# SAM9X75D1G device description
Architecture: ARM926EJ-S; Family: SAM9; Series: SAM9X7
Registers are 32-bit, read-write, reset 0x0 unless marked. A register's access mark holds for its fields unless they carry their own. Offsets are from the block's base; [hi:lo] are bit positions; {n}, {i} and the like mark numbered series.

## CSI — CSI Host Controller
Instances: CSI 0xF8058000
0x04 CSI_N_LANES reset 0x1 — CSI Lane Configuration Register
  [0] N_LANES — Number of active data lanes
0x08 CSI_CSI2_RESETN — CSI Reset Control Register
  [0] CSI2_RESETN — Internal controller logic reset
    0=Resets the internal controller logic; 1=CSI exits Reset state
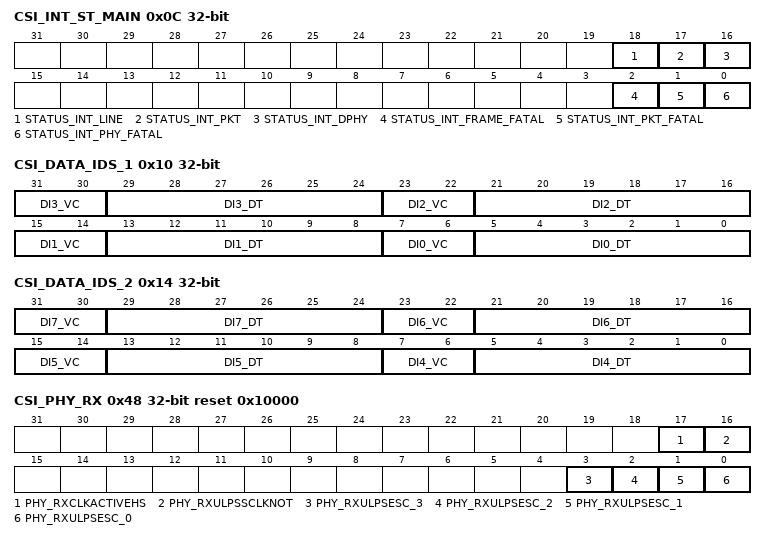
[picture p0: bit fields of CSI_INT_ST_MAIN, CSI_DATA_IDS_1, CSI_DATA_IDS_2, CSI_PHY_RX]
0x0C CSI_INT_ST_MAIN ro — CSI Main Interrupt Status Register
  [18] STATUS_INT_LINE — CSI_INT_LINE Register Event (Cleared on Read)
    0=No event occurred in the CSI_INT_ST_LINE register since the last CSI_INT_ST_MAIN read; 1=Indicates if an event occurred in the CSI_INT_ST_LINE register since the last CSI_INT_ST_MAIN read
  [17] STATUS_INT_PKT — CSI_INT_ST_PKT Register Event (Cleared on Read)
    0=No event occurred in the CSI_INT_ST_PKT register since the last CSI_INT_ST_MAIN read; 1=Indicates if an event occurred in the CSI_INT_ST_PKT register since the last CSI_INT_ST_MAIN read
  [16] STATUS_INT_DPHY — CSI_INT_ST_DPHY Register Event (Cleared on Read)
    0=No event occurred in the CSI_INT_ST_DPHY register since the last CSI_INT_ST_MAIN read; 1=Indicates if an event occurred in the CSI_INT_ST_DPHY register since the last CSI_INT_ST_MAIN read
  [2] STATUS_INT_FRAME_FATAL — CSI_INT_ST_FRAME_FATAL Register Event (Cleared on Read)
    0=No event occurred in the CSI_INT_ST_FRAME_FATAL register since the last CSI_INT_ST_MAIN read; 1=Indicates if an event occurred in the CSI_INT_ST_FRAME_FATAL register since the last CSI_INT_ST_MAIN read
  [1] STATUS_INT_PKT_FATAL — CSI_INT_ST_PKT_FATAL Register Event (Cleared on Read)
    0=No event occurred in the CSI_INT_ST_PKT_FATAL register since the last CSI_INT_ST_MAIN read; 1=Indicates if an event occurred in the CSI_INT_ST_PKT_FATAL register since the last CSI_INT_ST_MAIN read
  [0] STATUS_INT_PHY_FATAL — CSI_INT_ST_PHY_FATAL Register Event (Cleared on Read)
    0=No event occurred in the CSI_INT_ST_PHY_FATAL register since the last CSI_INT_ST_MAIN read; 1=Indicates if an event occurred in the CSI_INT_ST_PHY_FATAL register since the last CSI_INT_ST_MAIN read
0x10 CSI_DATA_IDS_1 — CSI Data Identifier Register 1
  [8n+7:8n+6] DI{n}_VC (n=0..3) — Virtual Channel for Programmed data ID {n}
  [8n+5:8n] DI{n}_DT (n=0..3) — Data Type for Programmed data ID {n}
0x14 CSI_DATA_IDS_2 — CSI Data Identifier Register 2
  [8n-25:8n-26] DI{n}_VC (n=4..7) — Virtual Channel for Programmed data ID {n}
  [8n-27:8n-32] DI{n}_DT (n=4..7) — Data Type for Programmed data ID {n}
0x40 CSI_PHY_SHUTDOWNZ — CSI D-PHY Shutdown Register
  [0] PHY_SHUTDOWNZ — Shutdown input buffer
    0=Puts the D-PHY in Shutdown mode. All analog blocks are in Power-down mode and digital logic is cleared.; 1=D-PHY exits Shutdown mode
0x44 CSI_DPHY_RSTZ — CSI D-PHY Reset Register
  [0] DPHY_RSTZ — D-PHY Reset Control
    0=Resets the D-PHY; 1=D-PHY exits Reset state
0x48 CSI_PHY_RX ro reset 0x10000 — CSI D-PHY Receive Status Register
  [17] PHY_RXCLKACTIVEHS — D-PHY Receives a DDR clock
    0=No DDR clock received; 1=Indicates that D-PHY clock lane is actively receiving a DDR clock
  [16] PHY_RXULPSSCLKNOT — Clock Lane Power Status
    0=Indicates that D-PHY Clock Lane module has entered the Ultra-Low-Power Mode; 1=Clock Lane is not ULP Mode
  [3] PHY_RXULPSESC_3 — Lane 3 Ultra-Low-Power Status
    0=Data lane 3 module is not in ULP Mode; 1=Data lane 3 module has entered ULP Mode
  [2] PHY_RXULPSESC_2 — Data Lane 2 Ultra-Low-Power Status
    0=Data lane 2 module is not in ULP Mode; 1=Data lane 2 module has entered ULP Mode
  [1] PHY_RXULPSESC_1 — Data Lane 1 Ultra-Low-Power Status
    0=Data lane 1 module is not in ULP Mode; 1=Data lane 1 module has entered ULP Mode
  [0] PHY_RXULPSESC_0 — Data Lane 0 Ultra-Low-Power Status
    0=Data lane 0 module is not in Ultra-Low-Power (ULP) Mode; 1=Data lane 0 module has entered ULP Mode
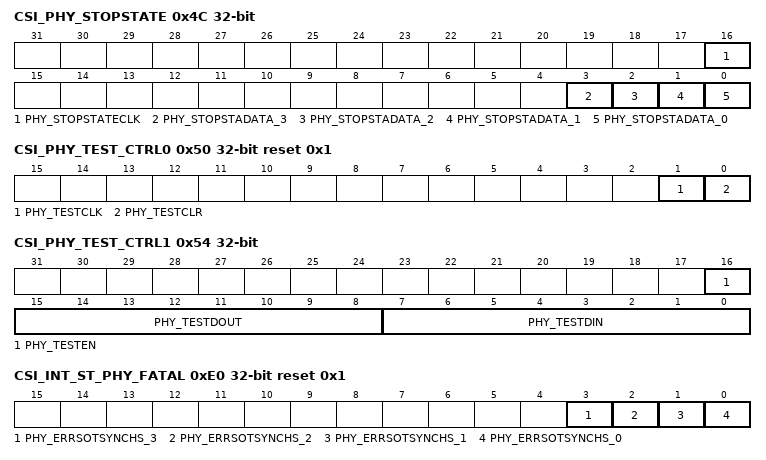
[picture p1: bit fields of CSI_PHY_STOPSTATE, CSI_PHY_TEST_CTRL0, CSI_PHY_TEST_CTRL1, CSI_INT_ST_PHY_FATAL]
0x4C CSI_PHY_STOPSTATE ro — CSI D-PHY Stop State Register
  [16] PHY_STOPSTATECLK — Clock Lane Stop State Status
    0=Clock lane module is not in Stop state; 1=Clock lane module is in Stop state
  [3] PHY_STOPSTADATA_3 — Data Lane 3 Stop State Status
    0=Data lane 3 module is not in Stop state; 1=Data lane 3 module has entered Stop state
  [2] PHY_STOPSTADATA_2 — Data Lane 2 Stop State Status
    0=Data lane 2 module is not in Stop state; 1=Data lane 2 module has entered Stop state
  [1] PHY_STOPSTADATA_1 — Data Lane 1 Stop State Status
    0=Lane 1 module is not in Stop state; 1=Lane 1 module has entered Stop state
  [0] PHY_STOPSTADATA_0 — Data Lane 0 Stop State Status
    0=Data lane 0 module is not in Stop state; 1=Lane 0 module has entered Stop state
0x50 CSI_PHY_TEST_CTRL0 reset 0x1 — CSI D-PHY Analog Configuration Control Register
  [1] PHY_TESTCLK — Analog Configuration Control Clock
    0=No effect; 1=Captures the PHY_TEST_CTRL1.PHY_TESTDIN value
  [0] PHY_TESTCLR — Analog Configuration Clear
    0=No effect; 1=Resets the analog configuration
0x54 CSI_PHY_TEST_CTRL1 — CSI D-PHY Analog Configuration Data Register
  [16] PHY_TESTEN — Analog Configuration Code Selection
    0=Transmits the high-speed bit rate code on the rising edge of CSI_PHY_TEST_CTRL0.PHY_TESTCLK; 1=Transmits the address (0x44) of the high-speed bit rate code on the falling edge of CSI_PHY_TEST_CTRL0.PHY_TESTCLK
  [15:8] PHY_TESTDOUT — Read Data Output for Test
  [7:0] PHY_TESTDIN — Analog Configuration Value or High-Speed Bit Rate Code
0xCC CSI_PHY_CAL ro — CSI D-PHY Calibration Status Register
  [0] RXSKEWCALHS — Calibration Status (cleared on read)
    0=No calibration initiated since the last CSI_PHY_CAL read; 1=A calibration has been initiated since the last CSI_PHY_CAL read
0xE0 CSI_INT_ST_PHY_FATAL ro reset 0x1 — CSI D-PHY Fatal Error Interrupt Status Register
  [3] PHY_ERRSOTSYNCHS_3 — Lane 3 Start Of Transmission Error Status (cleared on read)
    0=No transmission error has occurred on data lane 3 since the last read of CSI_INT_ST_PHY_FATAL; 1=Transmission error has occurred on data lane 3 since the last read of CSI_INT_ST_PHY_FATAL
  [2] PHY_ERRSOTSYNCHS_2 — Data Lane 2 Start Of Transmission Error Status (cleared on read)
    0=No transmission error has occurred on data lane 2 since the last read of CSI_INT_ST_PHY_FATAL; 1=Transmission error has occurred on data lane 2 since the last read of CSI_INT_ST_PHY_FATAL
  [1] PHY_ERRSOTSYNCHS_1 — Data Lane 1 Start Of Transmission Error Status (cleared on read)
    0=No transmission error has occurred on data lane 1 since the last read of CSI_INT_ST_PHY_FATAL; 1=Transmission error has occurred on data lane 1 since the last read of CSI_INT_ST_PHY_FATAL
  [0] PHY_ERRSOTSYNCHS_0 — Data Lane 0 Start Of Transmission Error Status (cleared on read)
    0=No transmission error has occurred on data lane 0 since the last read of CSI_INT_ST_PHY_FATAL; 1=Transmission error has occurred on data lane 0 since the last read of CSI_INT_ST_PHY_FATAL
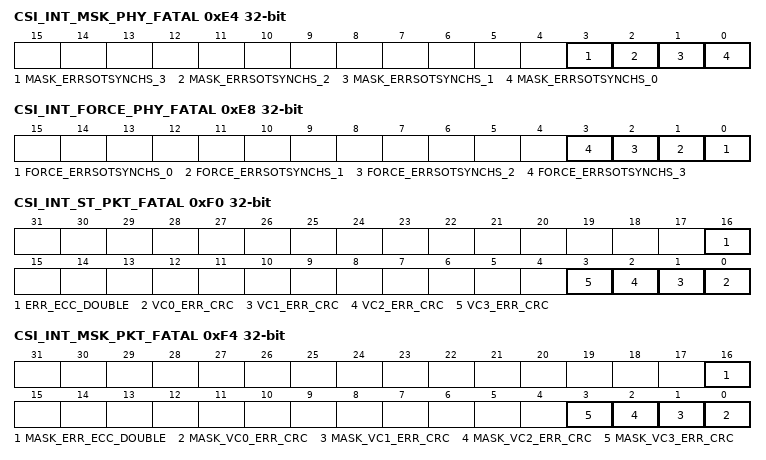
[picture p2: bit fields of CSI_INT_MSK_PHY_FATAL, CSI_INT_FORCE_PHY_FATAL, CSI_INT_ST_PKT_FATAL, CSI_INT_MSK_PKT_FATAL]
0xE4 CSI_INT_MSK_PHY_FATAL — CSI D-PHY Fatal Error Interrupt Mask Register
  [3] MASK_ERRSOTSYNCHS_3 — Lane 3 Start Of Transmission Error Error Interrupt Mask
  [2] MASK_ERRSOTSYNCHS_2 — Data Lane 2 Start Of Transmission Error Interrupt Mask
  [1] MASK_ERRSOTSYNCHS_1 — Data Lane 1 Start Of Transmission Error Interrupt Mask
  [0] MASK_ERRSOTSYNCHS_0 — Data Lane 0 Start Of Transmission Error Interrupt Mask
0xE8 CSI_INT_FORCE_PHY_FATAL — CSI D-PHY Fatal Error Interrupt Force Register
  [n] FORCE_ERRSOTSYNCHS_{n} (n=0..3) — Force Start Of Transmission Interrupt Error on Data Lane {n}
0xF0 CSI_INT_ST_PKT_FATAL ro — CSI Packet Fatal Error Interrupt Force Register
  [16] ERR_ECC_DOUBLE — Unrecoverable Header Error, Two Errors ECC, (cleared on read).
  [n] VC{n}_ERR_CRC (n=0..3) — Virtual Channel {n} Payload Checksum Error (cleared on read)
0xF4 CSI_INT_MSK_PKT_FATAL — CSI Packet Fatal Error Interrupt Force Register
  [16] MASK_ERR_ECC_DOUBLE — Unrecoverable Header Error (ECC Two Errors) Interrupt Mask
  [n] MASK_VC{n}_ERR_CRC (n=0..3) — Virtual Channel {n} Payload Checksum Error Interrupt Mask
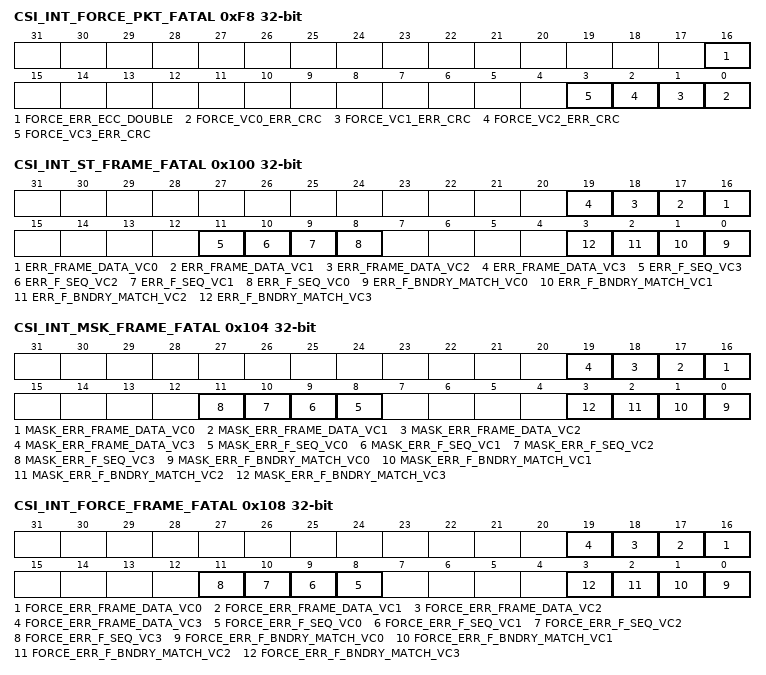
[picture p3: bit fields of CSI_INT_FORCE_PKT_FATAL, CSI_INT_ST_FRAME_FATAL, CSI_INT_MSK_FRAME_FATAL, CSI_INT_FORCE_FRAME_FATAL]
0xF8 CSI_INT_FORCE_PKT_FATAL — CSI Packet Fatal Error Interrupt Force Register
  [16] FORCE_ERR_ECC_DOUBLE — Force Header ECC Double Error Interrupt
  [n] FORCE_VC{n}_ERR_CRC (n=0..3) — Force Virtual Channel {n} Payload Checksum Error Interrupt
0x100 CSI_INT_ST_FRAME_FATAL ro — CSI Frame Fatal Error Interrupt Force Register
  [n+16] ERR_FRAME_DATA_VC{n} (n=0..3) — At Least One CRC Error in Last Received Frame of Virtual Channel {n} (cleared on read)
  [11] ERR_F_SEQ_VC3 — Incorrect Frame Sequence in Virtual Channel 3(cleared on read)
  [10] ERR_F_SEQ_VC2 — Incorrect Frame Sequence in Virtual Channel 2 (cleared on read)
  [9] ERR_F_SEQ_VC1 — Incorrect Frame Sequence in Virtual Channel 1 (cleared on read)
  [8] ERR_F_SEQ_VC0 — Incorrect Frame Sequence in Virtual Channel 0 (cleared on read)
  [n] ERR_F_BNDRY_MATCH_VC{n} (n=0..3) — Error Matching Frame Start with Frame End for Virtual Channel {n} (cleared on read)
0x104 CSI_INT_MSK_FRAME_FATAL — CSI Frame Fatal Error Interrupt Force Register
  [n+16] MASK_ERR_FRAME_DATA_VC{n} (n=0..3) — CRC Error in Last Received Frame of Virtual Channel {n} Interrupt Mask
  [n+8] MASK_ERR_F_SEQ_VC{n} (n=0..3) — Incorrect Frame Sequence in Virtual Channel {n} Interrupt Mask
  [n] MASK_ERR_F_BNDRY_MATCH_VC{n} (n=0..3) — Virtual Channel {n} Error Matching Frame Start with Frame End Interrupt Mask
0x108 CSI_INT_FORCE_FRAME_FATAL — CSI Frame Fatal Error Interrupt Force Register
  [n+16] FORCE_ERR_FRAME_DATA_VC{n} (n=0..3) — Force CRC Error in Last Received Frame of Virtual Channel {n} Interrupt Error
  [n+8] FORCE_ERR_F_SEQ_VC{n} (n=0..3) — Force Incorrect Frame Sequence in Virtual Channel {n} Interrupt Error
  [n] FORCE_ERR_F_BNDRY_MATCH_VC{n} (n=0..3) — Force Virtual Channel {n} Error Matching Frame Start with Frame End Interrupt Error
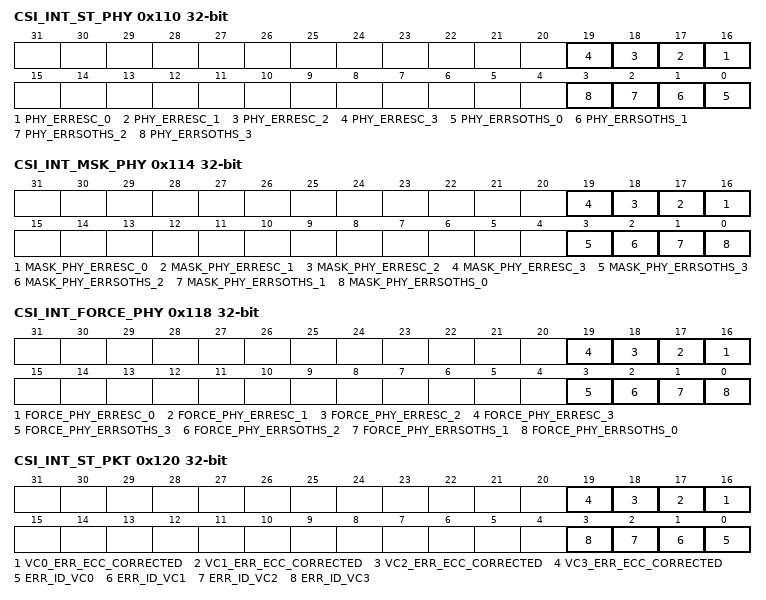
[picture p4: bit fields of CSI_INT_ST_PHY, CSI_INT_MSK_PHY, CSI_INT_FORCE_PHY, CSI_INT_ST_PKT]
0x110 CSI_INT_ST_PHY ro — CSI D-PHY Interrupt Status Register
  [n+16] PHY_ERRESC_{n} (n=0..3) — Start of Transmission Error on Data Lane {n} (synchronization can still be achieved) (cleared on read)
  [n] PHY_ERRSOTHS_{n} (n=0..3) — Start of Transmission Error on Data Lane {n} (no synchronization achieved) (cleared on read)
0x114 CSI_INT_MSK_PHY — CSI D-PHY Interrupt Mask Register
  [n+16] MASK_PHY_ERRESC_{n} (n=0..3) — Start of Transmission Error on Data Lane {n} (synchronization can still be achieved) Interrupt Mask
  [3] MASK_PHY_ERRSOTHS_3 — Start of Transmission Error on Data Lane 3 (no synchronization achieved) Interrupt Mask
  [2] MASK_PHY_ERRSOTHS_2 — Start of Transmission Error on Data Lane 2 (no synchronization achieved)Interrupt Mask
  [1] MASK_PHY_ERRSOTHS_1 — Start of Transmission Error on Data Lane 1 (no synchronization achieved) Interrupt Mask
  [0] MASK_PHY_ERRSOTHS_0 — Start of Transmission Error on Data Lane 0 (no synchronization achieved) Interrupt Mask
0x118 CSI_INT_FORCE_PHY — CSI D-PHY Interrupt Force Register
  [n+16] FORCE_PHY_ERRESC_{n} (n=0..3) — Force Start of Transmission Error on Data Lane {n} (synchronization can still be achieved) Interrupt
  [3] FORCE_PHY_ERRSOTHS_3 — Force Start of Transmission Error on Data Lane 3 (no synchronization achieved) Interrupt Mask
  [2] FORCE_PHY_ERRSOTHS_2 — Force Start of Transmission Error on Data Lane 2 (no synchronization achieved) Interrupt
  [1] FORCE_PHY_ERRSOTHS_1 — Force Start of Transmission Error on Data Lane 1 (no synchronization achieved) Interrupt
  [0] FORCE_PHY_ERRSOTHS_0 — Force Start of Transmission Error on Data Lane 0 (no synchronization achieved) Interrupt
0x120 CSI_INT_ST_PKT ro — CSI Packet Interrupt Status Register
  [n+16] VC{n}_ERR_ECC_CORRECTED (n=0..3) — Header Error Detected and Corrected on Virtual Channel {n} (cleared on read)
  [n] ERR_ID_VC{n} (n=0..3) — Unrecognized or Unimplemented Data Type Detected in Virtual Channel {n} (cleared on read)
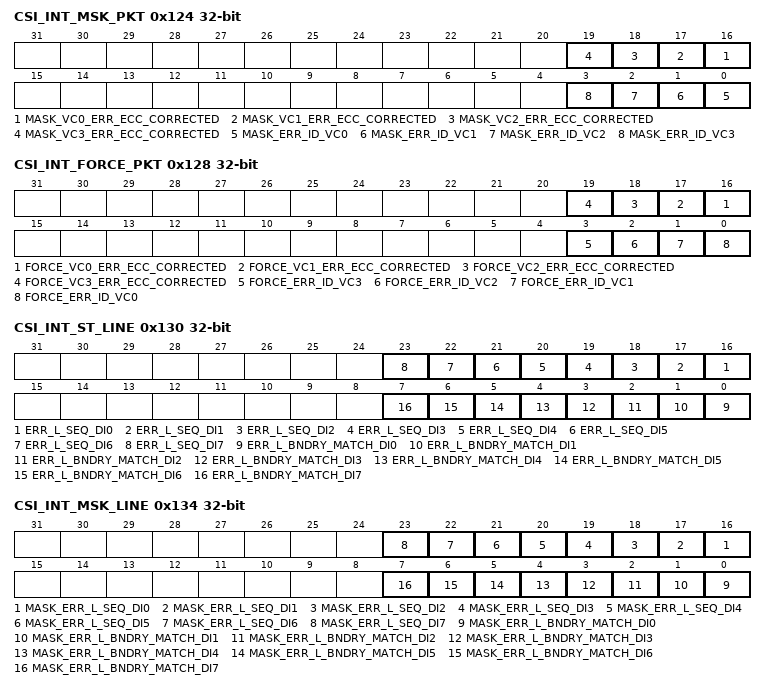
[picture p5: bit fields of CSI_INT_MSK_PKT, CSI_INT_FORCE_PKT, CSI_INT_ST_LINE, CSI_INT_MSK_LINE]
0x124 CSI_INT_MSK_PKT — CSI Packet Interrupt Mask Register
  [n+16] MASK_VC{n}_ERR_ECC_CORRECTED (n=0..3) — Header Error Detected and Corrected on Virtual Channel {n} Interrupt Mask
  [n] MASK_ERR_ID_VC{n} (n=0..3) — Unrecognized or Unimplemented Data Type Detected in Virtual Channel {n} Interrupt Mask
0x128 CSI_INT_FORCE_PKT — CSI Packet Interrupt Force Register
  [n+16] FORCE_VC{n}_ERR_ECC_CORRECTED (n=0..3) — Force Start of Transmission Error on Data Lane {n} (synchronization can still be achieved) Interrupt
  [3] FORCE_ERR_ID_VC3 — Force Start of Transmission Error on Data Lane 3 (no synchronization achieved) Interrupt Mask
  [2] FORCE_ERR_ID_VC2 — Force Start of Transmission Error on Data Lane 2 (no synchronization achieved) Interrupt
  [1] FORCE_ERR_ID_VC1 — Force Start of Transmission Error on Data Lane 1 (no synchronization achieved) Interrupt
  [0] FORCE_ERR_ID_VC0 — Force Start of Transmission Error on Data Lane 0 (no synchronization achieved) Interrupt
0x130 CSI_INT_ST_LINE ro — CSI Line Error Interrupt Status Register
  [n+16] ERR_L_SEQ_DI{n} (n=0..7) — Error in the Sequence of Lines for VC{n} and DT{n} (cleared on read)
  [n] ERR_L_BNDRY_MATCH_DI{n} (n=0..7) — Error Matching Line Start with Line End for VC{n} and DT{n} (cleared on read)
0x134 CSI_INT_MSK_LINE — CSI Line Error Interrupt Mask Register
  [n+16] MASK_ERR_L_SEQ_DI{n} (n=0..7) — Error in the Sequence of Lines for VC{n} and DT{n} Interrupt Mask
  [n] MASK_ERR_L_BNDRY_MATCH_DI{n} (n=0..7) — Error Matching Line Start with Line End for VC{n} and DT{n} Interrupt Mask
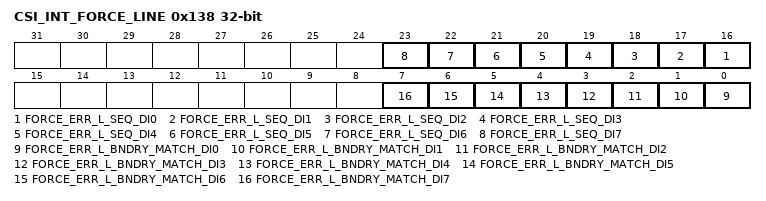
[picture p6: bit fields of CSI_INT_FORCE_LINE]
0x138 CSI_INT_FORCE_LINE — CSI Line Error Interrupt Force Register
  [n+16] FORCE_ERR_L_SEQ_DI{n} (n=0..7) — Force Error in the Sequence of Lines for VC{n} and DT{n} Interrupt
  [n] FORCE_ERR_L_BNDRY_MATCH_DI{n} (n=0..7) — Force Error Matching Line Start with Line End for VC{n} and DT{n} Interrupt
0x300 CSI_SCRAMBLING ro — CSI Descrambler Configuration Register
  [0] SCRAMBLE_ENABLE — Data De-scrambling Enable
    0=No data de-scrambling; 1=Activates the data de-scrambling
{0x304+4i} CSI_SCRAMBLING_SEED{i} (i=0..3) — CSI Lane {i} Scrambling Seed Register
  [15:0] SCRAMBLE_SEED_LANE{i} — Data Lane {i} Descrambler Seed
